VERSION ""

NS_ :

BS_:

BU_:

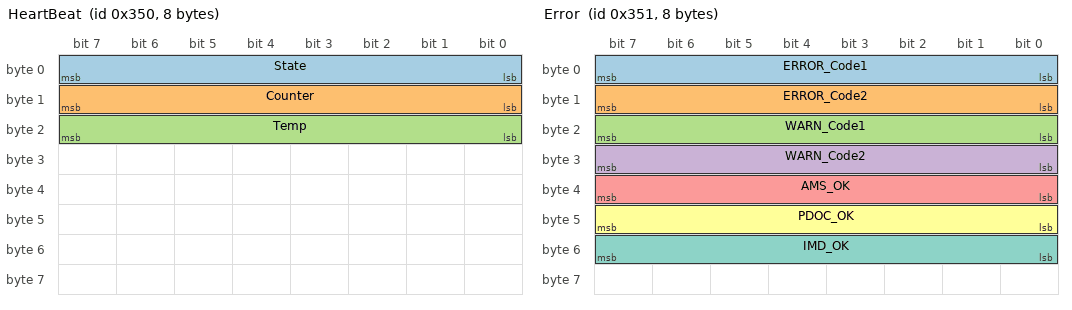
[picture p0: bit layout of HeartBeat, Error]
BO_ 848 HeartBeat: 8 Vector__XXX
 SG_ State : 0|8@1+ (1,0) [0|0] "" Vector__XXX
 SG_ Counter : 8|8@1+ (1,0) [0|0] "" Vector__XXX
 SG_ Temp : 16|8@1+ (1,0) [0|0] "" Vector__XXX

BO_ 849 Error: 8 Vector__XXX
 SG_ ERROR_Code1 : 0|8@1+ (1,0) [0|0] "" Vector__XXX
 SG_ ERROR_Code2 : 8|8@1+ (1,0) [0|0] "" Vector__XXX
 SG_ WARN_Code1 : 16|8@1+ (1,0) [0|0] "" Vector__XXX
 SG_ WARN_Code2 : 24|8@1+ (1,0) [0|0] "" Vector__XXX
 SG_ AMS_OK : 32|8@1+ (1,0) [0|0] "" Vector__XXX
 SG_ PDOC_OK : 40|8@1+ (1,0) [0|0] "" Vector__XXX
 SG_ IMD_OK : 48|8@1+ (1,0) [0|0] "" Vector__XXX

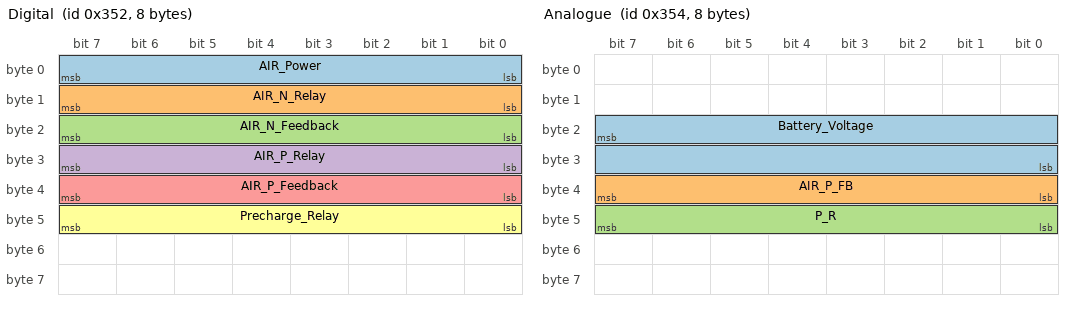
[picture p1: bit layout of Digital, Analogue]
BO_ 850 Digital: 8 Vector__XXX
 SG_ AIR_Power : 0|8@1+ (1,0) [0|0] "" Vector__XXX
 SG_ AIR_N_Relay : 8|8@1+ (1,0) [0|0] "" Vector__XXX
 SG_ AIR_N_Feedback : 16|8@1+ (1,0) [0|0] "" Vector__XXX
 SG_ AIR_P_Relay : 24|8@1+ (1,0) [0|0] "" Vector__XXX
 SG_ AIR_P_Feedback : 32|8@1+ (1,0) [0|0] "" Vector__XXX
 SG_ Precharge_Relay : 40|8@1+ (1,0) [0|0] "" Vector__XXX

BO_ 852 Analogue: 8 Vector__XXX
 SG_ Battery_Voltage : 23|16@0+ (1,0) [0|0] "Volts" Vector__XXX
 SG_ AIR_P_FB : 39|8@0+ (1,0) [0|0] "" Vector__XXX
 SG_ P_R : 47|8@0+ (1,0) [0|0] "" Vector__XXX
